# AT32F403xx_v2 register map
Vendor: Keil; Series: AT32F403; File version: 1.0
CPU: CM4 r0p1, little endian, no MPU, FPU, 4 interrupt priority bits
Registers are 32-bit, read-write, reset 0x0 unless marked. A register's access mark holds for its fields unless they carry their own. Offsets are from the block's base; [hi:lo] are bit positions; {n}, {i} and the like mark numbered series; 'fields as' and 'values as' point back to an identical list.

## DMA1 — DMA controller
Base 0x40020000
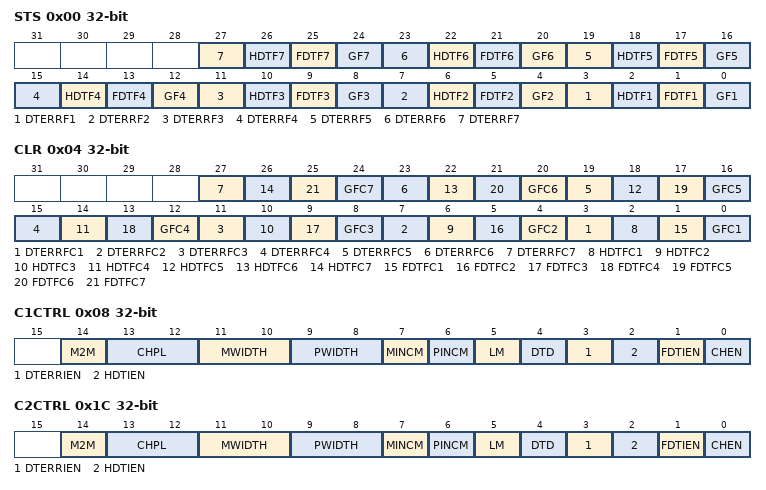
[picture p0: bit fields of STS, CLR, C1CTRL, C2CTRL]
0x00 STS ro — DMA interrupt status register (DMA_STS)
  [4n-1] DTERRF{n} (n=1..7) — Channel {n} data transfer error event flag
  [4n-2] HDTF{n} (n=1..7) — Channel {n} half data transfer event flag
  [4n-3] FDTF{n} (n=1..7) — Channel {n} full data transfer event flag
  [4n-4] GF{n} (n=1..7) — Channel {n} Global event flag
0x04 CLR — DMA interrupt flag clear register (DMA_CLR)
  [4n-1] DTERRFC{n} (n=1..7) — Channel {n} data transfer error flag clear
  [4n-2] HDTFC{n} (n=1..7) — Channel {n} half data transfer flag clear
  [4n-3] FDTFC{n} (n=1..7) — Channel {n} full data transfer flag clear
  [4n-4] GFC{n} (n=1..7) — Channel {n} Global flag clear
0x08 C1CTRL — DMA channel configuration register
  [14] M2M — Memory to memory mode
  [13:12] CHPL — Channel Priority level
  [11:10] MWIDTH — Memory data bit width
  [9:8] PWIDTH — Peripheral data bit width
  [7] MINCM — Memory address increment mode
  [6] PINCM — Peripheral address increment mode
  [5] LM — Loop mode
  [4] DTD — Data transfer direction
  [3] DTERRIEN — Data transfer error interrupt enable
  [2] HDTIEN — Half data transfer interrupt enable
  [1] FDTIEN — Full data transfer interrupt enable
  [0] CHEN — Channel enable
0x0C C1DTCNT — DMA channel 1 number of data to transfer register
  [15:0] CNT — Number of data to transfer
0x10 C1PADDR — DMA channel 1 peripheral base address register
  [31:0] PADDR — Peripheral address
{0x0+0x14*i} C{i}MADDR (i=1..5) — DMA channel {i} memory base address register
  [31:0] MADDR — Memory address
0x1C C2CTRL — DMA channel configuration register
  fields as C1CTRL
0x20 C2DTCNT — DMA channel 2 number of data to transferregister
  [15:0] CNT — Number of data to transfer
0x24 C2PADDR — DMA channel 2 peripheral base address register
  [31:0] PADDR — Peripheral address
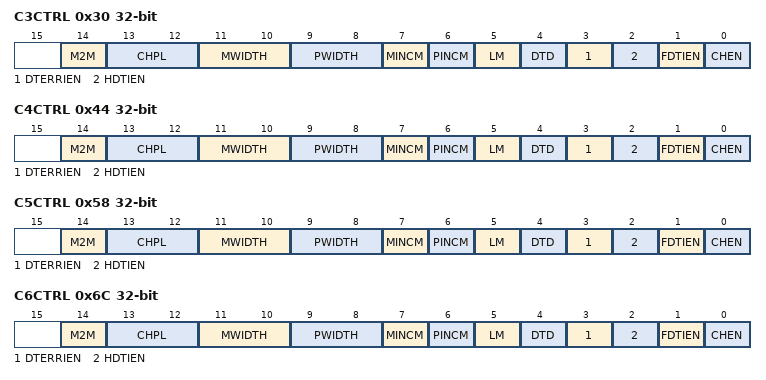
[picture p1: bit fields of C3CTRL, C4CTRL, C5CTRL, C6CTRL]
0x30 C3CTRL — DMA channel configuration register
  fields as C1CTRL
0x34 C3DTCNT — DMA channel 3 number of data to transfer register
  [15:0] CNT — Number of data to transfer
0x38 C3PADDR — DMA channel 3 peripheral base address register
  [31:0] PADDR — Peripheral address
0x44 C4CTRL — DMA channel configuration register
  fields as C1CTRL
0x48 C4DTCNT — DMA channel 4 number of data to transfer register
  [15:0] CNT — Number of data to transfer
0x4C C4PADDR — DMA channel 4 peripheral base address register
  [31:0] PADDR — Peripheral address
0x58 C5CTRL — DMA channel configuration register
  fields as C1CTRL
0x5C C5DTCNT — DMA channel 5 number of data to transfer register
  [15:0] CNT — Number of data to transfer
0x60 C5PADDR — DMA channel 5 peripheral base address register
  [31:0] PADDR — Peripheral address
0x6C C6CTRL — DMA channel configuration register
  fields as C1CTRL
0x70 C6DTCNT — DMA channel 6 number of data to transfer register
  [15:0] CNT — Number of data to transfer
0x74 C6PADDR — DMA channel 6 peripheral address base register
  [31:0] PADDR — Peripheral address
0x78 C6MADDR — DMA channel 6 memory address base register
  [31:0] MADDR — Memory address
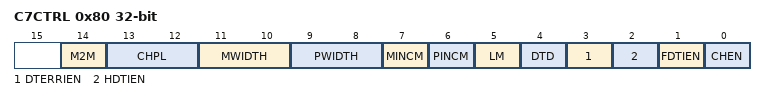
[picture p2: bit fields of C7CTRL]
0x80 C7CTRL — DMA channel configuration register
  fields as C1CTRL
0x84 C7DTCNT — DMA channel 7 number of data to transfer register
  [15:0] CNT — Number of data to transfer
0x88 C7PADDR — DMA channel 7 peripheral base address register
  [31:0] PADDR — Peripheral address
0x8C C7MADDR — DMA channel 7 memory base address register
  [31:0] MADDR — Memory address

## DMA2 — DMA controller
Base 0x40020400
Registers as DMA1, without C6CTRL, C6DTCNT, C6PADDR, C6MADDR, C7CTRL, C7DTCNT, C7PADDR, C7MADDR; these are added or differ:
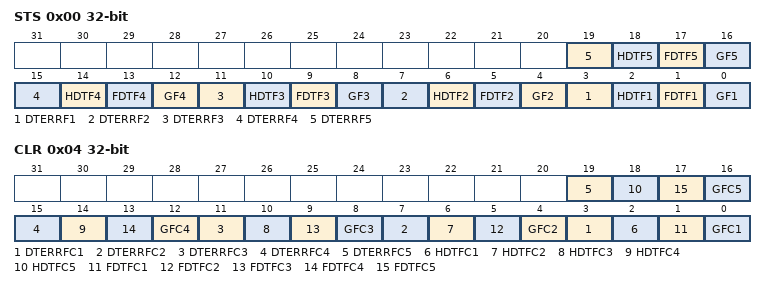
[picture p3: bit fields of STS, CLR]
0x00 STS ro — DMA interrupt status register (DMA_STS)
  [4n-1] DTERRF{n} (n=1..5) — Channel {n} data transfer error event flag
  [4n-2] HDTF{n} (n=1..5) — Channel {n} half data transfer event flag
  [4n-3] FDTF{n} (n=1..5) — Channel {n} full data transfer event flag
  [4n-4] GF{n} (n=1..5) — Channel {n} Global event flag
0x04 CLR — DMA interrupt flag clear register (DMA_CLR)
  [4n-1] DTERRFC{n} (n=1..5) — Channel {n} data transfer error flag clear
  [4n-2] HDTFC{n} (n=1..5) — Channel {n} half data transfer flag clear
  [4n-3] FDTFC{n} (n=1..5) — Channel {n} full data transfer flag clear
  [4n-4] GFC{n} (n=1..5) — Channel {n} Global flag clear

## Notices in the file
Copyright (C) 2012-2014 ARM Limited. All rights reserved.
Purpose: System Viewer Description (SVD) Example (Schema Version 1.1)
This is a description of a none-existent and incomplete device
for demonstration purposes only.
Redistribution and use in source and binary forms, with or without
modification, are permitted provided that the following conditions are met:
- Redistributions of source code must retain the above copyright
notice, this list of conditions and the following disclaimer.
- Redistributions in binary form must reproduce the above copyright
notice, this list of conditions and the following disclaimer in the
documentation and/or other materials provided with the distribution.
- Neither the name of ARM nor the names of its contributors may be used
to endorse or promote products derived from this software without
specific prior written permission.
THIS SOFTWARE IS PROVIDED BY THE COPYRIGHT HOLDERS AND CONTRIBUTORS "AS IS"
AND ANY EXPRESS OR IMPLIED WARRANTIES, INCLUDING, BUT NOT LIMITED TO, THE
IMPLIED WARRANTIES OF MERCHANTABILITY AND FITNESS FOR A PARTICULAR PURPOSE
ARE DISCLAIMED. IN NO EVENT SHALL COPYRIGHT HOLDERS AND CONTRIBUTORS BE
LIABLE FOR ANY DIRECT, INDIRECT, INCIDENTAL, SPECIAL, EXEMPLARY, OR
CONSEQUENTIAL DAMAGES (INCLUDING, BUT NOT LIMITED TO, PROCUREMENT OF
SUBSTITUTE GOODS OR SERVICES; LOSS OF USE, DATA, OR PROFITS; OR BUSINESS
INTERRUPTION) HOWEVER CAUSED AND ON ANY THEORY OF LIABILITY, WHETHER IN
CONTRACT, STRICT LIABILITY, OR TORT (INCLUDING NEGLIGENCE OR OTHERWISE)
ARISING IN ANY WAY OUT OF THE USE OF THIS SOFTWARE, EVEN IF ADVISED OF THE
POSSIBILITY OF SUCH DAMAGE.
